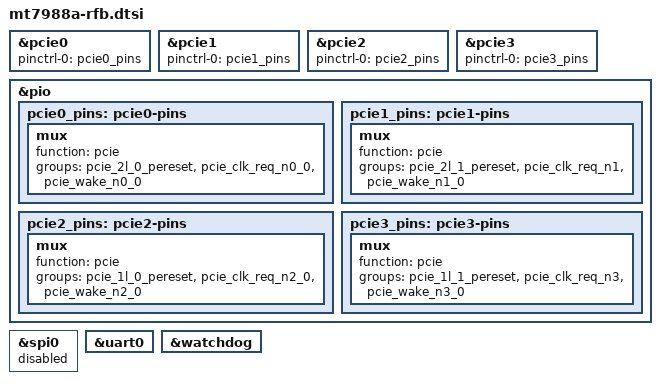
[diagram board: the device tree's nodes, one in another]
// SPDX-License-Identifier: (GPL-2.0 OR MIT)
/*
 * Copyright (C) 2022 MediaTek Inc.
 * Author: Sam.Shih <sam.shih@mediatek.com>
 */

/dts-v1/;
#include "mt7988a.dtsi"

&pcie0 {
	pinctrl-names = "default";
	pinctrl-0 = <&pcie0_pins>;
	status = "okay";
};

&pcie1 {
	pinctrl-names = "default";
	pinctrl-0 = <&pcie1_pins>;
	status = "okay";
};

&pcie2 {
	pinctrl-names = "default";
	pinctrl-0 = <&pcie2_pins>;
	status = "okay";
};

&pcie3 {
	pinctrl-names = "default";
	pinctrl-0 = <&pcie3_pins>;
	status = "okay";
};

&pio {
	pcie0_pins: pcie0-pins {
		mux {
			function = "pcie";
			groups = "pcie_2l_0_pereset", "pcie_clk_req_n0_0",
				 "pcie_wake_n0_0";
		};
	};

	pcie1_pins: pcie1-pins {
		mux {
			function = "pcie";
			groups = "pcie_2l_1_pereset", "pcie_clk_req_n1",
				 "pcie_wake_n1_0";
		};
	};

	pcie2_pins: pcie2-pins {
		mux {
			function = "pcie";
			groups = "pcie_1l_0_pereset", "pcie_clk_req_n2_0",
				 "pcie_wake_n2_0";
		};
	};

	pcie3_pins: pcie3-pins {
		mux {
			function = "pcie";
			groups = "pcie_1l_1_pereset", "pcie_clk_req_n3",
				 "pcie_wake_n3_0";
		};
	};
};

&spi0 {
	status = "disabled";
};

&uart0 {
	status = "okay";
};

&watchdog {
	status = "okay";
};
